# STM32H562 register map
File version: 0.1
CPU: CM33 r0p0, little endian, MPU, FPU, 4 interrupt priority bits
Registers are 32-bit, read-write, reset 0x0 unless marked. A register's access mark holds for its fields unless they carry their own. Offsets are from the block's base; [hi:lo] are bit positions.

## CRC — Cyclic redundancy check calculation unit
Base 0x40023000
Same registers: SEC_CRC 0x50023000
0x00 DR reset 0xFFFFFFFF — CRC data register
  [31:0] DR — Data register bits This register is used to write new data to the CRC calculator. It holds the previous CRC calculation result when it is read. If the data size is less than 32 bits, the least significant bits are used to write/read the correct value.
0x00 DR8 8-bit reset 0xFF (alternate view of DR) — Data register - byte sized
  [7:0] DR8 — Data register bits
0x00 DR16 16-bit reset 0xFFFF (alternate view of DR) — Data register - half-word sized
  [15:0] DR16 — Data register bits
0x04 IDR — CRC independent data register
  [31:0] GPDR — General-purpose 32-bit data register bits These bits can be used as a temporary storage location for four bytes. This register is not affected by CRC resets generated by the RESET bit in the CRC_CR register
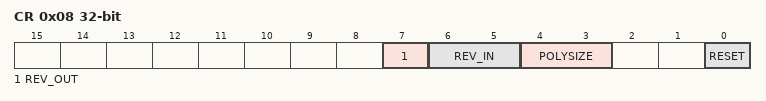
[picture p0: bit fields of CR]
0x08 CR — CRC control register
  [7] REV_OUT — Reverse output data This bit controls the reversal of the bit order of the output data.
    0=Normal (Bit order not affected); 1=Reversed (Bit reversed output)
  [6:5] REV_IN — Reverse input data These bits control the reversal of the bit order of the input data
    0=Normal (Bit order not affected); 1=Byte (Bit reversal done by byte); 2=HalfWord (Bit reversal done by half-word); 3=Word (Bit reversal done by word)
  [4:3] POLYSIZE — Polynomial size These bits control the size of the polynomial.
    0=32-bit polynomial; 1=16-bit polynomial; 2=8-bit polynomial; 3=7-bit polynomial
  [0] RESET — RESET bit This bit is set by software to reset the CRC calculation unit and set the data register to the value stored in the CRC_INIT register. This bit can only be set, it is automatically cleared by hardware
    on write: 1=Resets the CRC calculation unit and sets the data register to 0xFFFF FFFF
0x10 INIT reset 0xFFFFFFFF — CRC initial value
  [31:0] INIT — Programmable initial CRC value This register is used to write the CRC initial value.
0x14 POL reset 0x4C11DB7 — CRC polynomial
  [31:0] POL — Programmable polynomial This register is used to write the coefficients of the polynomial to be used for CRC calculation. If the polynomial size is less than 32 bits, the least significant bits have to be used to program the correct value.

## DCACHE — Data cache
Base 0x40031400
Same registers: SEC_DCACHE 0x50031400
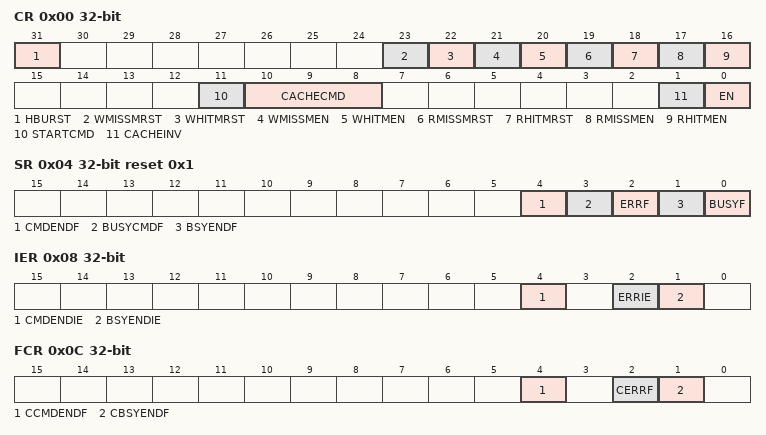
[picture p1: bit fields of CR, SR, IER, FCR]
0x00 CR access per field — DCACHE control register
  [31] HBURST rw — output burst type for cache master port read accesses Write access is always done in INCR burst type.
  [23] WMISSMRST rw — write-miss monitor reset
  [22] WHITMRST rw — write-hit monitor reset
  [21] WMISSMEN rw — write-miss monitor enable
  [20] WHITMEN rw — write-hit monitor enable
  [19] RMISSMRST rw — read-miss monitor reset
  [18] RHITMRST rw — read-hit monitor reset
  [17] RMISSMEN rw — read-miss monitor enable
  [16] RHITMEN rw — read-hit monitor enable
  [11] STARTCMD wo — starts maintenance command (maintenance operation defined in CACHECMD). Can be set by software, only when EN = 1, BUSYCMDF = 0, BUSYF = 0 and CACHECMD = 0b001, 0b010 or 0b011. Cleared by hardware when the BUSYCMDF flag is set (during cache maintenance operation). Writing 0 has no effect.
  [10:8] CACHECMD rw — cache command maintenance operation (cleans and/or invalidates an address range) Can be set and cleared by software, only when no maintenance command is ongoing (BUSYCMDF = 0). others: reserved
  [1] CACHEINV wo — full cache invalidation Can be set by software, only when EN = 1. Cleared by hardware when the BUSYF flag is set (during full cache invalidation operation). Writing 0 has no effect.
  [0] EN rw — enable
0x04 SR ro reset 0x1 — DCACHE status register
  [4] CMDENDF — command end flag Cleared by writing DCACHE_FCR.CCMDENDF = 1.
  [3] BUSYCMDF — command busy flag
  [2] ERRF — cache error flag Cleared by writing DCACHE_FCR.CERRF = 1.
  [1] BSYENDF — full invalidate busy end flag Cleared by writing DCACHE_FCR.CBSYENDF = 1.
  [0] BUSYF — full invalidate busy flag
0x08 IER — DCACHE interrupt enable register
  [4] CMDENDIE — interrupt enable on command end Set by software to enable an interrupt generation at the end of a cache command (clean and/or invalidate an address range)
  [2] ERRIE — interrupt enable on cache error Set by software to enable an interrupt generation in case of cache functional error (eviction or clean operation write-back error)
  [1] BSYENDIE — interrupt enable on busy end Set by SW to enable an interrupt generation at the end of a cache full invalidate operation.
0x0C FCR wo — DCACHE flag clear register
  [4] CCMDENDF — clear command end flag Set by software.
  [2] CERRF — clear cache error flag Set by software.
  [1] CBSYENDF — clear full invalidate busy end flag Set by software.
0x10 RHMONR ro — DCACHE read-hit monitor register
  [31:0] RHITMON — cache read-hit monitor counter
0x14 RMMONR ro — DCACHE read-miss monitor register
  [15:0] RMISSMON — cache read-miss monitor counter
0x20 WHMONR ro — DCACHE write-hit monitor register
  [31:0] WHITMON — cache write-hit monitor counter
0x24 WMMONR ro — DCACHE write-miss monitor register
  [15:0] WMISSMON — cache write-miss monitor counter
0x28 CMDRSADDRR — DCACHE command range start address register
  [31:4] CMDSTARTADDR — start address of range to which the cache maintenance command specified in DCACHE_CR.CACHECMD field applies This register must be set before DCACHE_CR.CACHECMD is written. .
0x2C CMDREADDRR — DCACHE command range end address register
  [31:4] CMDENDADDR — end address of range to which the cache maintenance command specified in DCACHE_CR.CACHECMD field applies This register must be set before DCACHE_CR.CACHECMD is written.
